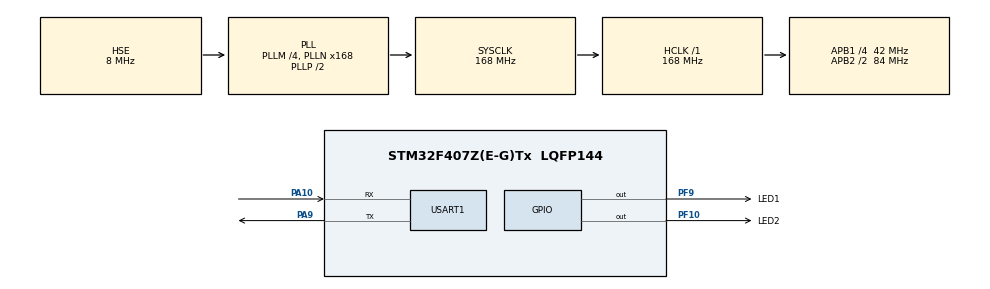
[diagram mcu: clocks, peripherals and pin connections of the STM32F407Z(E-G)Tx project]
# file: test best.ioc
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Mcu.Family=STM32F4
Mcu.Name=STM32F407Z(E-G)Tx
Mcu.Package=LQFP144
NVIC.PriorityGroup=NVIC_PRIORITYGROUP_4
NVIC.USART1_IRQn=true\:1\:0\:true\:false\:true\:true
PA10.Mode=Asynchronous
PA10.Signal=USART1_RX
PA9.Mode=Asynchronous
PA9.Signal=USART1_TX
PF10.GPIO_Label=LED2
PF10.Signal=GPIO_Output
PF9.GPIO_Label=LED1
PF9.Signal=GPIO_Output
PH0-OSC_IN.Mode=HSE-External-Oscillator
PH0-OSC_IN.Signal=RCC_OSC_IN
PH1-OSC_OUT.Mode=HSE-External-Oscillator
PH1-OSC_OUT.Signal=RCC_OSC_OUT
ProjectManager.HeapSize=0x200
ProjectManager.StackSize=0x400
ProjectManager.TargetToolchain=MDK-ARM V5
RCC.48MHZClocksFreq_Value=84000000
RCC.AHBFreq_Value=168000000
RCC.APB1CLKDivider=RCC_HCLK_DIV4
RCC.APB1Freq_Value=42000000
RCC.APB1TimFreq_Value=84000000
RCC.APB2CLKDivider=RCC_HCLK_DIV2
RCC.APB2Freq_Value=84000000
RCC.APB2TimFreq_Value=168000000
RCC.CortexFreq_Value=168000000
RCC.EnbaleCSS=true
RCC.HCLKFreq_Value=168000000
RCC.HSE_VALUE=8000000
RCC.HSI_VALUE=16000000
RCC.LSE_VALUE=32768
RCC.PLLM=4
RCC.PLLN=168
RCC.PLLSourceVirtual=RCC_PLLSOURCE_HSE
RCC.SYSCLKFreq_VALUE=168000000
RCC.SYSCLKSource=RCC_SYSCLKSOURCE_PLLCLK
RCC.VCOOutputFreq_Value=336000000
USART1.VirtualMode=VM_ASYNC
board=custom

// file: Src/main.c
/**
  ******************************************************************************
  * @file           : main.c
  * @brief          : Main program body
  ******************************************************************************
  ** This notice applies to any and all portions of this file
  * that are not between comment pairs USER CODE BEGIN and
  * USER CODE END. Other portions of this file, whether
  * inserted by the user or by software development tools
  * are owned by their respective copyright owners.
  *
  * COPYRIGHT(c) 2019 STMicroelectronics
  *
  * Redistribution and use in source and binary forms, with or without modification,
  * are permitted provided that the following conditions are met:
  *   1. Redistributions of source code must retain the above copyright notice,
  *      this list of conditions and the following disclaimer.
  *   2. Redistributions in binary form must reproduce the above copyright notice,
  *      this list of conditions and the following disclaimer in the documentation
  *      and/or other materials provided with the distribution.
  *   3. Neither the name of STMicroelectronics nor the names of its contributors
  *      may be used to endorse or promote products derived from this software
  *      without specific prior written permission.
  *
  * THIS SOFTWARE IS PROVIDED BY THE COPYRIGHT HOLDERS AND CONTRIBUTORS "AS IS"
  * AND ANY EXPRESS OR IMPLIED WARRANTIES, INCLUDING, BUT NOT LIMITED TO, THE
  * IMPLIED WARRANTIES OF MERCHANTABILITY AND FITNESS FOR A PARTICULAR PURPOSE ARE
  * DISCLAIMED. IN NO EVENT SHALL THE COPYRIGHT HOLDER OR CONTRIBUTORS BE LIABLE
  * FOR ANY DIRECT, INDIRECT, INCIDENTAL, SPECIAL, EXEMPLARY, OR CONSEQUENTIAL
  * DAMAGES (INCLUDING, BUT NOT LIMITED TO, PROCUREMENT OF SUBSTITUTE GOODS OR
  * SERVICES; LOSS OF USE, DATA, OR PROFITS; OR BUSINESS INTERRUPTION) HOWEVER
  * CAUSED AND ON ANY THEORY OF LIABILITY, WHETHER IN CONTRACT, STRICT LIABILITY,
  * OR TORT (INCLUDING NEGLIGENCE OR OTHERWISE) ARISING IN ANY WAY OUT OF THE USE
  * OF THIS SOFTWARE, EVEN IF ADVISED OF THE POSSIBILITY OF SUCH DAMAGE.
  *
  ******************************************************************************
  */
#include "main.h"
#include "stm32f4xx_hal.h"
#include "usart.h"
#include "gpio.h"

/* USER CODE BEGIN Includes */
#include "string.h"
/* USER CODE END Includes */

/* USER CODE BEGIN PV */
/* Private variables ---------------------------------------------------------*/
uint8_t aRxBuffer;
/* USER CODE END PV */

void SystemClock_Config(void);

/* USER CODE BEGIN PFP */
/* Private function prototypes -----------------------------------------------*/

/* USER CODE END PFP */

int main(void)
{
  /* USER CODE BEGIN 1 */
	uint8_t txbuf[100];
  /* USER CODE END 1 */

  /* MCU Configuration----------------------------------------------------------*/

  /* Reset of all peripherals, Initializes the Flash interface and the Systick. */
  HAL_Init();

  /* Configure the system clock */
  SystemClock_Config();

  /* Initialize all configured peripherals */
  MX_GPIO_Init();
  MX_USART1_UART_Init();
  /* USER CODE BEGIN 2 */
	LED1_ON;
	LED2_ON;
  memcpy(txbuf,"这是一个串口中断接收回显实验\n",100);
  HAL_UART_Transmit(&huart1,txbuf,strlen((char *)txbuf),1000);

  memcpy(txbuf,"输入数据并以回车键结束\n",100);
  HAL_UART_Transmit(&huart1,txbuf,strlen((char *)txbuf),1000);

  /* 使能接收，进入中断回调函数 */
  HAL_UART_Receive_IT(&huart1,&aRxBuffer,1);

  /* USER CODE END 2 */

  /* Infinite loop */
  while (1)
  {
		LED1_TOGGLE;
		HAL_Delay(500);
		LED2_TOGGLE;
		HAL_Delay(500);
  }

}

void SystemClock_Config(void)
{

  RCC_OscInitTypeDef RCC_OscInitStruct;
  RCC_ClkInitTypeDef RCC_ClkInitStruct;

    /**Configure the main internal regulator output voltage
    */
  __HAL_RCC_PWR_CLK_ENABLE();

  __HAL_PWR_VOLTAGESCALING_CONFIG(PWR_REGULATOR_VOLTAGE_SCALE1);

    /**Initializes the CPU, AHB and APB busses clocks
    */
  RCC_OscInitStruct.OscillatorType = RCC_OSCILLATORTYPE_HSE;
  RCC_OscInitStruct.HSEState = RCC_HSE_ON;
  RCC_OscInitStruct.PLL.PLLState = RCC_PLL_ON;
  RCC_OscInitStruct.PLL.PLLSource = RCC_PLLSOURCE_HSE;
  RCC_OscInitStruct.PLL.PLLM = 4;
  RCC_OscInitStruct.PLL.PLLN = 168;
  RCC_OscInitStruct.PLL.PLLP = RCC_PLLP_DIV2;
  RCC_OscInitStruct.PLL.PLLQ = 4;
  if (HAL_RCC_OscConfig(&RCC_OscInitStruct) != HAL_OK)
  {
    _Error_Handler(__FILE__, __LINE__);
  }

    /**Initializes the CPU, AHB and APB busses clocks
    */
  RCC_ClkInitStruct.ClockType = RCC_CLOCKTYPE_HCLK|RCC_CLOCKTYPE_SYSCLK
                              |RCC_CLOCKTYPE_PCLK1|RCC_CLOCKTYPE_PCLK2;
  RCC_ClkInitStruct.SYSCLKSource = RCC_SYSCLKSOURCE_PLLCLK;
  RCC_ClkInitStruct.AHBCLKDivider = RCC_SYSCLK_DIV1;
  RCC_ClkInitStruct.APB1CLKDivider = RCC_HCLK_DIV4;
  RCC_ClkInitStruct.APB2CLKDivider = RCC_HCLK_DIV2;

  if (HAL_RCC_ClockConfig(&RCC_ClkInitStruct, FLASH_LATENCY_5) != HAL_OK)
  {
    _Error_Handler(__FILE__, __LINE__);
  }

    /**Enables the Clock Security System
    */
  HAL_RCC_EnableCSS();

    /**Configure the Systick interrupt time
    */
  HAL_SYSTICK_Config(HAL_RCC_GetHCLKFreq()/1000);

    /**Configure the Systick
    */
  HAL_SYSTICK_CLKSourceConfig(SYSTICK_CLKSOURCE_HCLK);

  /* SysTick_IRQn interrupt configuration */
  HAL_NVIC_SetPriority(SysTick_IRQn, 0, 0);
}

/* USER CODE BEGIN 4 */
void HAL_UART_RxCpltCallback(UART_HandleTypeDef *UartHandle)
{
  HAL_UART_Transmit(&huart1,&aRxBuffer,1,0);
  HAL_UART_Receive_IT(&huart1,&aRxBuffer,1);
}
/* USER CODE END 4 */

void _Error_Handler(char *file, int line)
{
  while(1)
  {
  }
}

/************************ (C) COPYRIGHT STMicroelectronics *****END OF FILE****/
